# GD32E230 register map
File version: 1.0
CPU: CM23 r1p0, little endian, no MPU, no FPU, 4 interrupt priority bits
Registers are 32-bit, read-write, reset 0x0 unless marked. A register's access mark holds for its fields unless they carry their own. Offsets are from the block's base; [hi:lo] are bit positions; {n}, {i} and the like mark numbered series.

## I2C0 — Inter integrated circuit
Base 0x40005400
Same registers: I2C1 0x40005800
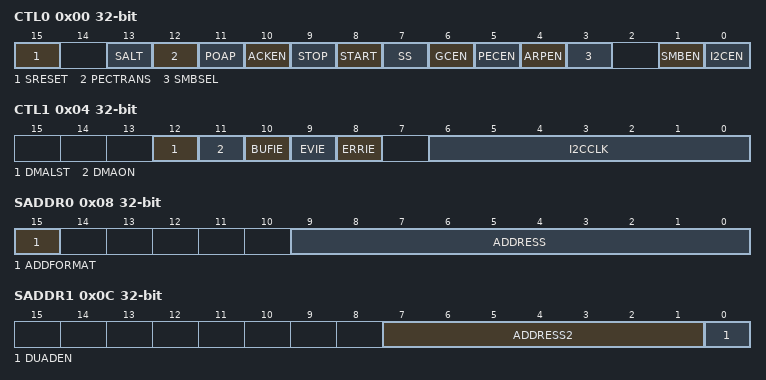
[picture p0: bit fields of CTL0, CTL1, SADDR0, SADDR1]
0x00 CTL0 — Control register 0
  [15] SRESET — Software reset
  [13] SALT — SMBus alert
  [12] PECTRANS — Packet error checking
  [11] POAP — Acknowledge/PEC Position (for data reception)
  [10] ACKEN — Acknowledge enable
  [9] STOP — Stop condition
  [8] START — Start generation
  [7] SS — SCL Stretching(Slave mode)
  [6] GCEN — General call enable
  [5] PECEN — PEC enable
  [4] ARPEN — ARP enable
  [3] SMBSEL — SMBus type
  [1] SMBEN — SMBus mode
  [0] I2CEN — Peripheral enable
0x04 CTL1 — Control register 1
  [12] DMALST — Flag indicating DMA last transfer
  [11] DMAON — DMA mode switch
  [10] BUFIE — Buffer interrupt enable
  [9] EVIE — Event interrupt enable
  [8] ERRIE — Error interrupt enable
  [6:0] I2CCLK — Peripheral clock frequency
0x08 SADDR0 — Own address register 0
  [15] ADDFORMAT — Addressing mode (slave mode)
  [9:0] ADDRESS — Interface address
0x0C SADDR1 — Own address register 1
  [7:1] ADDRESS2 — Interface address
  [0] DUADEN — Dual addressing mode enable
0x10 DATA
  [7:0] TRB — Transmission or reception data buffer
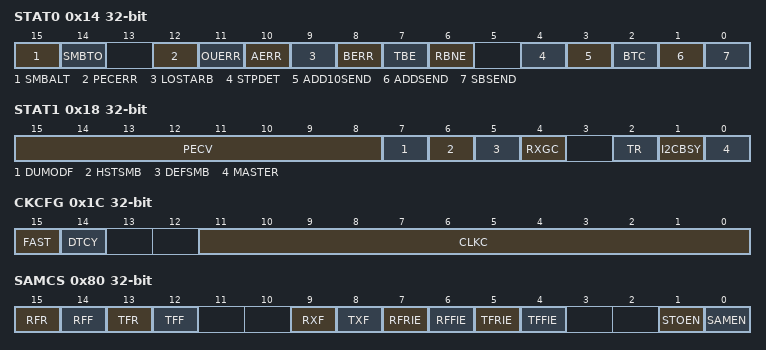
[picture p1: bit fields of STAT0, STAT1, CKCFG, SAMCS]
0x14 STAT0 access per field — Transfer status register 0
  [15] SMBALT rw — SMBus alert
  [14] SMBTO rw — Timeout signal in SMBus mode
  [12] PECERR rw — PEC error when receiving data
  [11] OUERR rw — Overrun/Underrun occurs in slave mode
  [10] AERR rw — Acknowledge error
  [9] LOSTARB rw — Arbitration lost (master mode)
  [8] BERR rw — Bus error
  [7] TBE ro — I2C_DATA is Empty during transmitting
  [6] RBNE ro — I2C_DATA is not Empty during receiving
  [4] STPDET ro — Stop detection (slave mode)
  [3] ADD10SEND ro — Header of 10-bit address is sent in master mode
  [2] BTC ro — Byte transmission completed
  [1] ADDSEND ro — Address sent (master mode)/matched (slave mode)
  [0] SBSEND ro — Start bit (Master mode)
0x18 STAT1 ro — Transfer status register 1
  [15:8] PECV — Packet error checking register
  [7] DUMODF — Dual flag (Slave mode)
  [6] HSTSMB — SMBus host header (Slave mode)
  [5] DEFSMB — SMBus device default address (Slave mode)
  [4] RXGC — General call address (Slave mode)
  [2] TR — Transmitter/receiver
  [1] I2CBSY — Bus busy
  [0] MASTER — Master/slave
0x1C CKCFG — Clock configure register
  [15] FAST — I2C master mode selection
  [14] DTCY — Fast mode duty cycle
  [11:0] CLKC — Clock control register in Fast/Standard mode (Master mode)
0x20 RT reset 0x2 — Rise time register
  [6:0] RISETIME — Maximum rise time in master mode
0x80 SAMCS — SAM control and status register
  [15] RFR — Rxframe rise flag
  [14] RFF — Rxframe fall flag
  [13] TFR — Txframe rise flag
  [12] TFF — Txframe fall flag
  [9] RXF — level of rx frame signal
  [8] TXF — level of tx frame signal
  [7] RFRIE — Rx frame rise interrupt enable
  [6] RFFIE — Rx frame fall interrupt enable
  [5] TFRIE — Tx frame rise interrupt enable
  [4] TFFIE — Tx frame fall interrupt enable
  [1] STOEN — SAM_V interface timeout detect enable
  [0] SAMEN — SAM_V interface enable
0x90 FMPCFG — Fast-mode-plus configure register
  [0] FMPEN — Fast-mode-plus enable

## NVIC — Nested Vectored Interrupt Controller
Base 0xE000E100
{0x0+4i} ISER{i} (i=0..15) — Interrupt Set Enable Register
  [31:0] SETENA
0x80 ICER0 — Interrupt Clear Enable Register
  [31:0] CLRENA
0x84 ICER1 — Interrupt Clear Enable Register
  [31:0] CLRENA
{0x84+4i} ICER{i} (i=2..15) — Interrupt Clear Enable Register
  [31:0] CLRENA
{0x100+4i} ISPR{i} (i=0..15) — Interrupt Set-Pending Register
  [31:0] SETPEND
{0x180+4i} ICPR{i} (i=0..15) — Interrupt Clear-Pending Register
  [31:0] CLRPEND
{0x200+4i} IABR{i} (i=0..15) — Interrupt Active bit Register
  [31:0] IABR
{0x280+4i} ITNS{i} (i=0..15) — Interrupt Active bit Register
  [31:0] ITNS
{0x300+i} IPR{i} 8-bit (i=0..31) — Interrupt Priority Register {i}
  [7:0] PRI_{i:02}
